# ESP32-H4 register map
Vendor: ESPRESSIF SYSTEMS (SHANGHAI) CO., LTD.; Series: ESP32 H-Series; File version: 1
CPU: RV32IMAC r0p0, little endian, no MPU, no FPU, 0 interrupt priority bits
Address unit: 32 bits
Registers are 32-bit, read-write, reset 0x0 unless marked. A register's access mark holds for its fields unless they carry their own. Offsets are from the block's base; [hi:lo] are bit positions; {n}, {i} and the like mark numbered series.

## MODEM_LPCON
Base 0x600CF000
0x00 TEST_CONF
  [0] CLK_EN
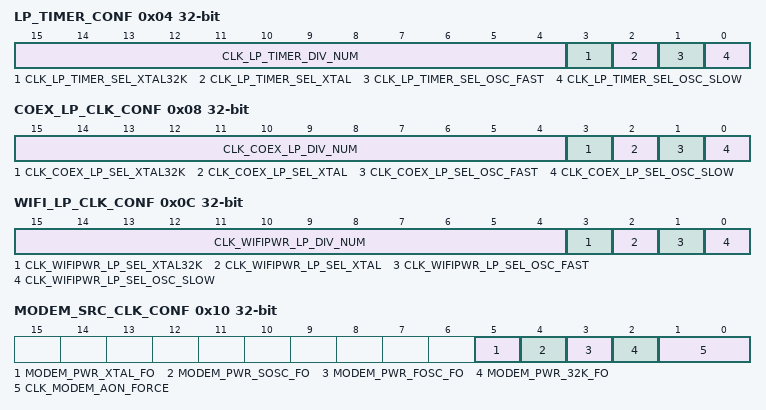
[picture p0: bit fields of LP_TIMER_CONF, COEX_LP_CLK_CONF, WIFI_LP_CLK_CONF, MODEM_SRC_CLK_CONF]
0x04 LP_TIMER_CONF
  [15:4] CLK_LP_TIMER_DIV_NUM, [3] CLK_LP_TIMER_SEL_XTAL32K, [2] CLK_LP_TIMER_SEL_XTAL, [1] CLK_LP_TIMER_SEL_OSC_FAST, [0] CLK_LP_TIMER_SEL_OSC_SLOW
0x08 COEX_LP_CLK_CONF
  [15:4] CLK_COEX_LP_DIV_NUM, [3] CLK_COEX_LP_SEL_XTAL32K, [2] CLK_COEX_LP_SEL_XTAL, [1] CLK_COEX_LP_SEL_OSC_FAST, [0] CLK_COEX_LP_SEL_OSC_SLOW
0x0C WIFI_LP_CLK_CONF
  [15:4] CLK_WIFIPWR_LP_DIV_NUM, [3] CLK_WIFIPWR_LP_SEL_XTAL32K, [2] CLK_WIFIPWR_LP_SEL_XTAL, [1] CLK_WIFIPWR_LP_SEL_OSC_FAST, [0] CLK_WIFIPWR_LP_SEL_OSC_SLOW
0x10 MODEM_SRC_CLK_CONF
  [5] MODEM_PWR_XTAL_FO, [4] MODEM_PWR_SOSC_FO, [3] MODEM_PWR_FOSC_FO, [2] MODEM_PWR_32K_FO, [1:0] CLK_MODEM_AON_FORCE
0x14 MODEM_32K_CLK_CONF
  [1:0] CLK_MODEM_32K_SEL
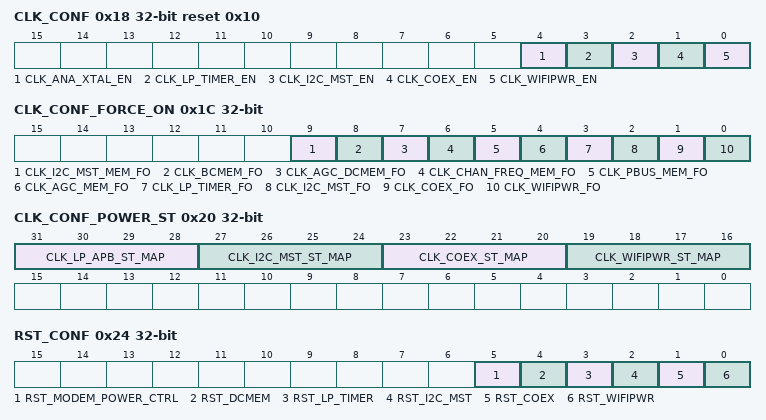
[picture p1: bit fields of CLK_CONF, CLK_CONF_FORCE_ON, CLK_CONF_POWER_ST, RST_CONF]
0x18 CLK_CONF reset 0x10
  [4] CLK_ANA_XTAL_EN, [3] CLK_LP_TIMER_EN, [2] CLK_I2C_MST_EN, [1] CLK_COEX_EN, [0] CLK_WIFIPWR_EN
0x1C CLK_CONF_FORCE_ON
  [9] CLK_I2C_MST_MEM_FO, [8] CLK_BCMEM_FO, [7] CLK_AGC_DCMEM_FO, [6] CLK_CHAN_FREQ_MEM_FO, [5] CLK_PBUS_MEM_FO, [4] CLK_AGC_MEM_FO, [3] CLK_LP_TIMER_FO, [2] CLK_I2C_MST_FO, [1] CLK_COEX_FO, [0] CLK_WIFIPWR_FO
0x20 CLK_CONF_POWER_ST
  [31:28] CLK_LP_APB_ST_MAP, [27:24] CLK_I2C_MST_ST_MAP, [23:20] CLK_COEX_ST_MAP, [19:16] CLK_WIFIPWR_ST_MAP
0x24 RST_CONF wo
  [5] RST_MODEM_POWER_CTRL, [4] RST_DCMEM, [3] RST_LP_TIMER, [2] RST_I2C_MST, [1] RST_COEX, [0] RST_WIFIPWR
0x28 TICK_CONF reset 0x27
  [5:0] MODEM_PWR_TICK_TARGET
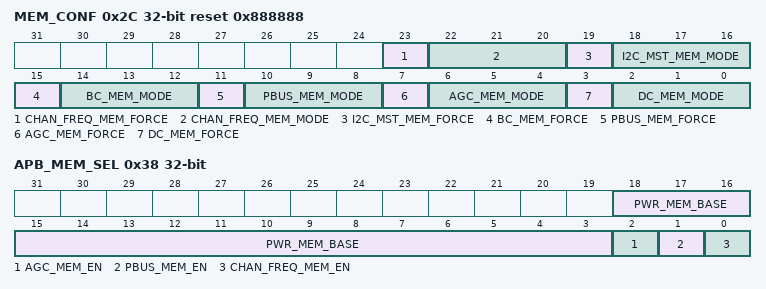
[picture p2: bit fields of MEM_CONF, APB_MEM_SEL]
0x2C MEM_CONF reset 0x888888
  [23] CHAN_FREQ_MEM_FORCE, [22:20] CHAN_FREQ_MEM_MODE, [19] I2C_MST_MEM_FORCE, [18:16] I2C_MST_MEM_MODE, [15] BC_MEM_FORCE, [14:12] BC_MEM_MODE, [11] PBUS_MEM_FORCE, [10:8] PBUS_MEM_MODE, [7] AGC_MEM_FORCE, [6:4] AGC_MEM_MODE, [3] DC_MEM_FORCE, [2:0] DC_MEM_MODE
0x30 MEM_RF1_AUX_CTRL reset 0x2070
  [31:0] MODEM_PWR_RF1_AUX_CTRL
0x34 MEM_RF2_AUX_CTRL
  [31:0] MODEM_PWR_RF2_AUX_CTRL
0x38 APB_MEM_SEL
  [18:3] PWR_MEM_BASE, [2] AGC_MEM_EN, [1] PBUS_MEM_EN, [0] CHAN_FREQ_MEM_EN
{0x3C+4i} DCMEM_VALID_{i} ro (i=0..3)
0x4C DATE

## I2C_ANA_MST — I2C_ANA_MST Peripheral
Base 0x600CF800
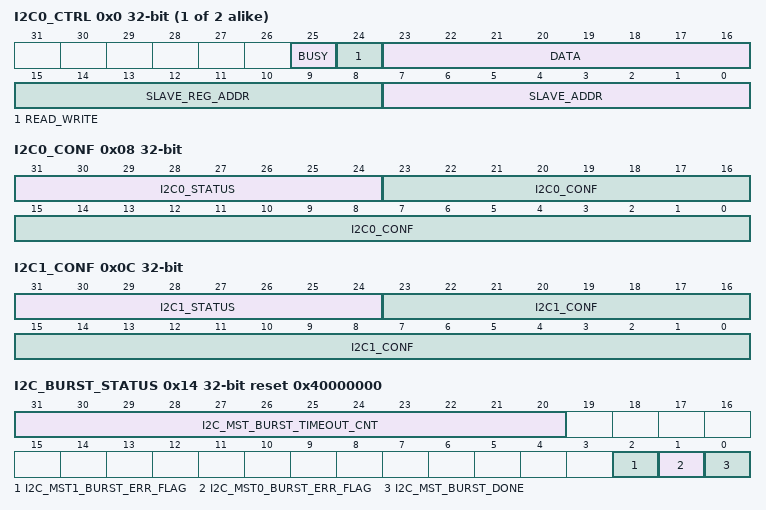
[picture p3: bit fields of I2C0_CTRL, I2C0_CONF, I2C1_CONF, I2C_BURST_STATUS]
{0x0+4i} I2C{i}_CTRL (i=0..1) — I2C{i}_CTRL
  [25] BUSY ro, [24] READ_WRITE, [23:16] DATA, [15:8] SLAVE_REG_ADDR, [7:0] SLAVE_ADDR
0x08 I2C0_CONF
  [31:24] I2C0_STATUS ro, [23:0] I2C0_CONF
0x0C I2C1_CONF
  [31:24] I2C1_STATUS ro, [23:0] I2C1_CONF
0x10 I2C_BURST_CONF
  [31:0] I2C_MST_BURST_CTRL
0x14 I2C_BURST_STATUS reset 0x40000000
  [31:20] I2C_MST_BURST_TIMEOUT_CNT, [2] I2C_MST1_BURST_ERR_FLAG, [1] I2C_MST0_BURST_ERR_FLAG, [0] I2C_MST_BURST_DONE
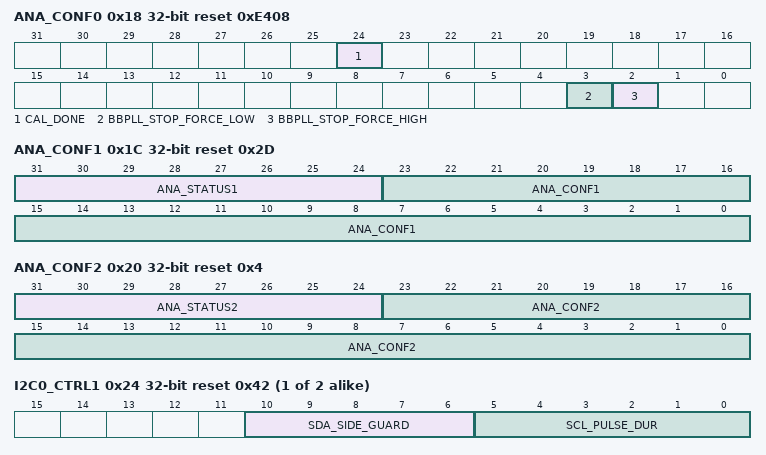
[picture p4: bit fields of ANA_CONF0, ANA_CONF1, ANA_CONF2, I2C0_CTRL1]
0x18 ANA_CONF0 reset 0xE408
  [24] CAL_DONE ro — BBPLL calibration done
  [3] BBPLL_STOP_FORCE_LOW — Start the BBPLL calibration
  [2] BBPLL_STOP_FORCE_HIGH — Stop the BBPLL calibration
0x1C ANA_CONF1 reset 0x2D
  [31:24] ANA_STATUS1, [23:0] ANA_CONF1
0x20 ANA_CONF2 reset 0x4
  [31:24] ANA_STATUS2, [23:0] ANA_CONF2
{0x24+4i} I2C{i}_CTRL1 (i=0..1) reset 0x42 — I2C{i}_CTRL1
  [10:6] SDA_SIDE_GUARD, [5:0] SCL_PULSE_DUR
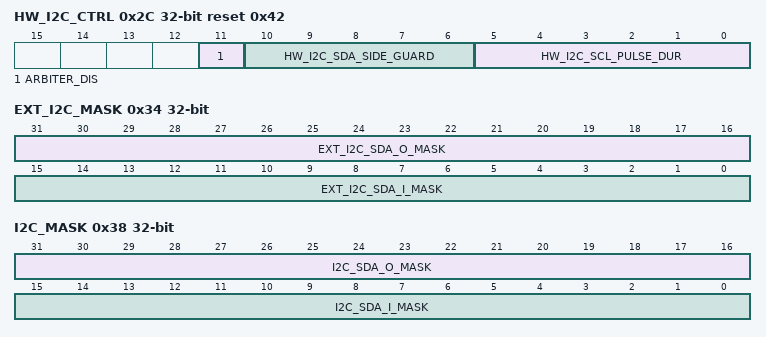
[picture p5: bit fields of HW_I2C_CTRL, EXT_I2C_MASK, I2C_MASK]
0x2C HW_I2C_CTRL reset 0x42
  [11] ARBITER_DIS, [10:6] HW_I2C_SDA_SIDE_GUARD, [5:0] HW_I2C_SCL_PULSE_DUR
0x30 I2C_MST_NOUSE
0x34 EXT_I2C_MASK
  [31:16] EXT_I2C_SDA_O_MASK, [15:0] EXT_I2C_SDA_I_MASK
0x38 I2C_MASK
  [31:16] I2C_SDA_O_MASK, [15:0] I2C_SDA_I_MASK
0x3C DATE

## USB_WRAP — USB_WRAP Peripheral
Base 0x60080000
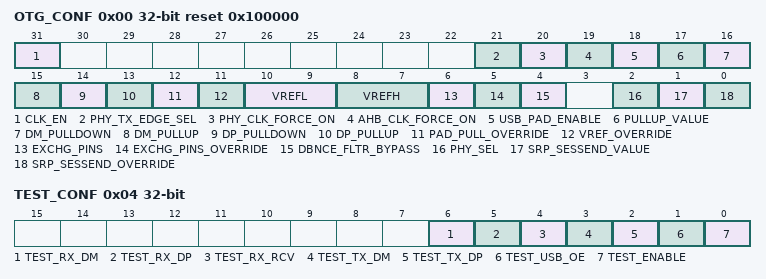
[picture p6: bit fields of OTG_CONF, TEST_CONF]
0x00 OTG_CONF reset 0x100000 — USB wrapper configuration registers.
  [31] CLK_EN — Disable auto clock gating of CSR registers.
  [21] PHY_TX_EDGE_SEL — Select phy tx signal output clock edge. 1'b0: negedge, 1'b1: posedge.
  [20] PHY_CLK_FORCE_ON — Force phy clock always on.
  [19] AHB_CLK_FORCE_ON — Force ahb clock always on.
  [18] USB_PAD_ENABLE — Enable USB pad function.
  [17] PULLUP_VALUE — Controlle pullup value. 1'b0: typical value is 2.4K, 1'b1: typical value is 1.2K.
  [16] DM_PULLDOWN — Controlle USB D+ pulldown.
  [15] DM_PULLUP — Controlle USB D+ pullup.
  [14] DP_PULLDOWN — Controlle USB D+ pulldown.
  [13] DP_PULLUP — Controlle USB D+ pullup.
  [12] PAD_PULL_OVERRIDE — Enable software controlle USB D+ D- pullup pulldown.
  [11] VREF_OVERRIDE — Enable software controlle input threshold.
  [10:9] VREFL — Control single-end input low threshold,0.8V to 1.04V, step 80mV.
  [8:7] VREFH — Control single-end input high threshold,1.76V to 2V, step 80mV.
  [6] EXCHG_PINS — USB D+ D- exchange. 1'b0: don't change, 1'b1: exchange D+ D-.
  [5] EXCHG_PINS_OVERRIDE — Enable software controlle USB D+ D- exchange
  [4] DBNCE_FLTR_BYPASS — Bypass Debounce filters for avalid,bvalid,vbusvalid,session end, id signals
  [2] PHY_SEL — Select internal external PHY. 1'b0: Select internal PHY, 1'b1: Select external PHY.
  [1] SRP_SESSEND_VALUE — Software over-ride value of srp session end signal.
  [0] SRP_SESSEND_OVERRIDE — This bit is used to enable the software over-ride of srp session end signal. 1'b0: the signal is controlled by the chip input, 1'b1: the signal is controlled by the software.
0x04 TEST_CONF access per field — USB wrapper test configuration registers.
  [6] TEST_RX_DM ro — USB D- rx value in test.
  [5] TEST_RX_DP ro — USB D+ rx value in test.
  [4] TEST_RX_RCV ro — USB differential rx value in test.
  [3] TEST_TX_DM rw — USB D- tx value in test.
  [2] TEST_TX_DP rw — USB D+ tx value in test.
  [1] TEST_USB_OE rw — USB pad oen in test.
  [0] TEST_ENABLE rw — Enable test of the USB pad.
0x3FC DATE
